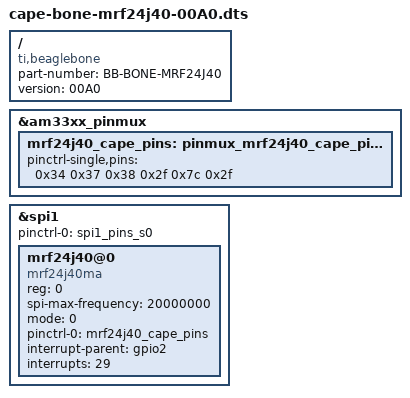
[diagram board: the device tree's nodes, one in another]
/*
 * Copyright (C) 2013 Alan Ott <alan@signal11.us>
 *
 * This program is free software; you can redistribute it and/or modify
 * it under the terms of the GNU General Public License version 2 as
 * published by the Free Software Foundation.
 */

/dts-v1/;
/plugin/;

/ {
	compatible = "ti,beaglebone", "ti-beaglebone-black";

	/* Identification */
	part-number = "BB-BONE-MRF24J40";
	version = "00A0";

	fragment@0 {
		target = <&am33xx_pinmux>;
		__overlay__ {
			mrf24j40_cape_pins: pinmux_mrf24j40_cape_pins {
				pinctrl-single,pins = <
					/* Pinmux comes from TRM section
					   9.3.1: CONTROL_MODULE Regusters. */
					//0x44 0x2f /* gpmc_a1.gpio1_17 INPUT,no-pull,mode7 */
					//0x1A4 0x2f /* mcasp0_fsr.gpio3_19 INPUT,no-pull,mode7 */
					//0x00 0x2f /* gpmc_ad0.gpio1_0 */

					//so use GPIO1_13 (rst), GPIO1_14 (wake), then SPI1_CS0 (CS), and GPIO1_29 (INT)
					0x34 0x37 /* gpmc_ad13.gpio1_13 input, pull up, mode 7 */
					0x38 0x2f /* gpmc_ad14.gpio1_14 input, no pull, mode 7 */
					//0x13c 0x2f /* gpmc_ad15.gpio1_15 input, no pull, mode 7 */
					0x7c 0x2f /* gpmc_csn0.gpio1_29 input, no pull, mode 7 */
				>;
			};
		};

	};


	fragment@1 {
		target = <&spi1>;

		__overlay__ {
			/* needed to avoid DTC warnings */
			#address-cells = <1>;
			#size-cells = <0>;

			status = "okay";
			pinctrl-names = "default";
			pinctrl-0 = <&spi1_pins_s0>;

			mrf24j40@0 {
				compatible = "mrf24j40ma";
				reg = <0>; /* CHIPSEL */
				spi-max-frequency = <20000000>;
				mode = <0>;
				pinctrl-names = "default";
				pinctrl-0 = <&mrf24j40_cape_pins>;

				interrupt-parent = <&gpio2>;
				interrupts = <29>;

				// also working feb 9
				//interrupt-parent = <&gpio2>;
				//interrupts = <0>;

				//working configuration
				//interrupt-parent = <&gpio2>;
				//interrupts = <17>;

				//mrf24j40-wake = <&gpio4 19>;
				//mrf24j40-reset = <gpio21 0>;
			};
		};
	};
};
